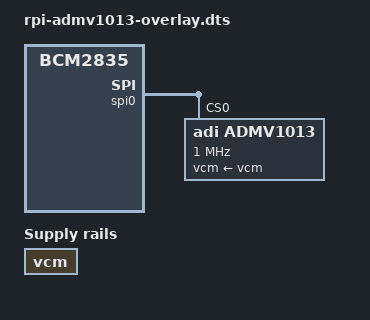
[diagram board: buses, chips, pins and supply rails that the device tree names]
// SPDX-License-Identifier: GPL-2.0
/dts-v1/;
/plugin/;

/ {
	compatible = "brcm,bcm2835";
};

&spidev0 {
	status = "disabled";
};

&{/} {
	clocks {
		admv1013_lo: clock@0 {
			compatible = "fixed-clock";

			clock-frequency = <100000000>;
			clock-output-names = "lo_in";
			#clock-cells = <0>;
		};
	};
};

&{/} {
	vcm: fixedregulator@0 {
		compatible = "regulator-fixed";
		regulator-name = "vcm";
		regulator-min-microvolt = <0>;
		regulator-max-microvolt = <0>;
		regulator-boot-on;
	};
};

&spi0 {
	#address-cells = <1>;
	#size-cells = <0>;
	status = "okay";

	admv1013@0 {
		compatible = "adi,admv1013";
		reg = <0>;
		spi-max-frequency = <1000000>;
		clocks = <&admv1013_lo>;
		clock-names = "lo_in";
		clock-scales = <1 5>;
		vcm-supply = <&vcm>;
		adi,quad-se-mode = <12>;
		adi,parity-en;
	};
};
